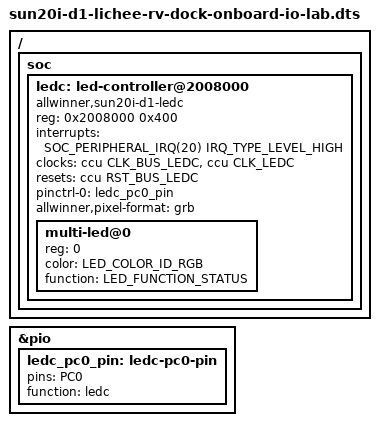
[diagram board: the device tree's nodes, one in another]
// SPDX-License-Identifier: (GPL-2.0+ OR MIT)

#include "sun20i-d1-lichee-rv-dock-spi-i2c-lab.dts"

/* Зелёный PC1 наследуется от sun20i-d1-lichee-rv.dts. */
/ {
	soc {
		ledc: led-controller@2008000 {
			compatible = "allwinner,sun20i-d1-ledc",
				     "allwinner,sun50i-a100-ledc";
			reg = <0x2008000 0x400>;
			interrupts = <SOC_PERIPHERAL_IRQ(20) IRQ_TYPE_LEVEL_HIGH>;
			clocks = <&ccu CLK_BUS_LEDC>, <&ccu CLK_LEDC>;
			clock-names = "bus", "mod";
			resets = <&ccu RST_BUS_LEDC>;
			pinctrl-0 = <&ledc_pc0_pin>;
			pinctrl-names = "default";
			allwinner,pixel-format = "grb";
			#address-cells = <1>;
			#size-cells = <0>;
			status = "okay";

			/* Без DMA драйвер использует PIO. */
			multi-led@0 {
				reg = <0>;
				color = <LED_COLOR_ID_RGB>;
				function = LED_FUNCTION_STATUS;
			};
		};
	};
};

&pio {
	ledc_pc0_pin: ledc-pc0-pin {
		pins = "PC0";
		function = "ledc";
	};
};
